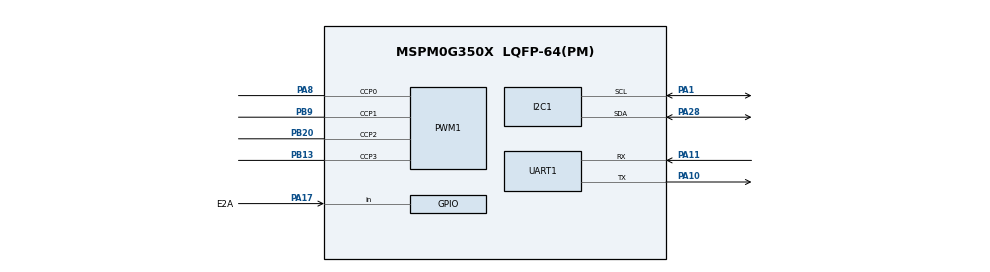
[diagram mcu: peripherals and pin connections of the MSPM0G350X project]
/**
 *
 * @cliArgs --device "MSPM0G350X" --part "Default" --package "LQFP-64(PM)" --product "mspm0_sdk@2.10.00.04"
 * @versions {"tool":"1.28.1+4785"}
 */

/**
 * Import the modules used in this configuration.
 */
const ADC12   = scripting.addModule("/ti/driverlib/ADC12", {}, false);
const ADC121  = ADC12.addInstance();
const GPIO    = scripting.addModule("/ti/driverlib/GPIO", {}, false);
const GPIO1   = GPIO.addInstance();
const GPIO2   = GPIO.addInstance();
const GPIO3   = GPIO.addInstance();
const GPIO4   = GPIO.addInstance();
const GPIO5   = GPIO.addInstance();
const GPIO6   = GPIO.addInstance();
const GPIO7   = GPIO.addInstance();
const GPIO8   = GPIO.addInstance();
const GPIO9   = GPIO.addInstance();
const GPIO10  = GPIO.addInstance();
const GPIO11  = GPIO.addInstance();
const GPIO12  = GPIO.addInstance();
const GPIO13  = GPIO.addInstance();
const GPIO14  = GPIO.addInstance();
const GPIO15  = GPIO.addInstance();
const I2C     = scripting.addModule("/ti/driverlib/I2C", {}, false);
const I2C1    = I2C.addInstance();
const PWM     = scripting.addModule("/ti/driverlib/PWM", {}, false);
const PWM1    = PWM.addInstance();
const SYSCTL  = scripting.addModule("/ti/driverlib/SYSCTL");
const SYSTICK = scripting.addModule("/ti/driverlib/SYSTICK");
const TIMER   = scripting.addModule("/ti/driverlib/TIMER", {}, false);
const TIMER1  = TIMER.addInstance();
const UART    = scripting.addModule("/ti/driverlib/UART", {}, false);
const UART1   = UART.addInstance();

/**
 * Write custom configuration values to the imported modules.
 */
const gate7  = system.clockTree["MFCLKGATE"];
gate7.enable = true;

ADC121.$name                      = "ADC12_0";
ADC121.sampClkSrc                 = "DL_ADC12_CLOCK_ULPCLK";
ADC121.repeatMode                 = true;
ADC121.sampleTime0                = "2 us";
ADC121.peripheral.adcPin0.$assign = "PA27";
ADC121.adcPin0Config.$name        = "ti_driverlib_gpio_GPIOPinGeneric8";

const Board = scripting.addModule("/ti/driverlib/Board", {}, false);

GPIO1.$name                          = "LED1";
GPIO1.associatedPins[0].$name        = "PIN_0";
GPIO1.associatedPins[0].assignedPort = "PORTA";
GPIO1.associatedPins[0].assignedPin  = "0";
GPIO1.associatedPins[0].initialValue = "SET";

GPIO2.$name                              = "KEY";
GPIO2.associatedPins.create(3);
GPIO2.associatedPins[0].direction        = "INPUT";
GPIO2.associatedPins[0].internalResistor = "PULL_UP";
GPIO2.associatedPins[0].assignedPort     = "PORTB";
GPIO2.associatedPins[0].assignedPin      = "21";
GPIO2.associatedPins[0].$name            = "button1";
GPIO2.associatedPins[1].$name            = "button2";
GPIO2.associatedPins[1].direction        = "INPUT";
GPIO2.associatedPins[1].assignedPort     = "PORTB";
GPIO2.associatedPins[1].assignedPin      = "23";
GPIO2.associatedPins[1].internalResistor = "PULL_UP";
GPIO2.associatedPins[2].$name            = "button3";
GPIO2.associatedPins[2].direction        = "INPUT";
GPIO2.associatedPins[2].assignedPort     = "PORTA";
GPIO2.associatedPins[2].assignedPin      = "23";
GPIO2.associatedPins[2].internalResistor = "PULL_UP";

GPIO3.$name                          = "ENCODERA";
GPIO3.associatedPins.create(2);
GPIO3.associatedPins[0].$name        = "E1A";
GPIO3.associatedPins[0].direction    = "INPUT";
GPIO3.associatedPins[0].assignedPort = "PORTA";
GPIO3.associatedPins[0].interruptEn  = true;
GPIO3.associatedPins[0].polarity     = "RISE";
GPIO3.associatedPins[0].assignedPin  = "15";
GPIO3.associatedPins[1].$name        = "E1B";
GPIO3.associatedPins[1].direction    = "INPUT";
GPIO3.associatedPins[1].assignedPort = "PORTA";
GPIO3.associatedPins[1].assignedPin  = "16";
GPIO3.associatedPins[1].interruptEn  = true;
GPIO3.associatedPins[1].polarity     = "RISE";

GPIO4.$name                          = "ENCODERB";
GPIO4.associatedPins.create(2);
GPIO4.associatedPins[0].$name        = "E2A";
GPIO4.associatedPins[0].direction    = "INPUT";
GPIO4.associatedPins[0].assignedPort = "PORTA";
GPIO4.associatedPins[0].assignedPin  = "17";
GPIO4.associatedPins[0].polarity     = "RISE";
GPIO4.associatedPins[0].interruptEn  = true;
GPIO4.associatedPins[0].pin.$assign  = "PA17";
GPIO4.associatedPins[1].$name        = "E2B";
GPIO4.associatedPins[1].direction    = "INPUT";
GPIO4.associatedPins[1].assignedPort = "PORTA";
GPIO4.associatedPins[1].assignedPin  = "22";
GPIO4.associatedPins[1].interruptEn  = true;
GPIO4.associatedPins[1].polarity     = "RISE";

GPIO5.$name                          = "AIN1";
GPIO5.associatedPins[0].$name        = "PIN_12";
GPIO5.associatedPins[0].assignedPort = "PORTB";
GPIO5.associatedPins[0].assignedPin  = "2";

GPIO6.$name                          = "AIN2";
GPIO6.associatedPins[0].$name        = "PIN_13";
GPIO6.associatedPins[0].assignedPort = "PORTB";
GPIO6.associatedPins[0].assignedPin  = "3";

GPIO7.$name                          = "BIN1";
GPIO7.associatedPins[0].$name        = "Pin_Bin1";
GPIO7.associatedPins[0].assignedPort = "PORTB";
GPIO7.associatedPins[0].assignedPin  = "16";

GPIO8.$name                          = "BIN2";
GPIO8.associatedPins[0].$name        = "Pin_Bin2";
GPIO8.associatedPins[0].assignedPort = "PORTB";
GPIO8.associatedPins[0].assignedPin  = "0";

GPIO9.$name                          = "ENCODERC";
GPIO9.associatedPins.create(2);
GPIO9.associatedPins[0].$name        = "PIN_1";
GPIO9.associatedPins[0].direction    = "INPUT";
GPIO9.associatedPins[0].assignedPort = "PORTB";
GPIO9.associatedPins[0].assignedPin  = "6";
GPIO9.associatedPins[0].interruptEn  = true;
GPIO9.associatedPins[0].polarity     = "RISE";
GPIO9.associatedPins[1].$name        = "PIN_2";
GPIO9.associatedPins[1].direction    = "INPUT";
GPIO9.associatedPins[1].assignedPort = "PORTB";
GPIO9.associatedPins[1].assignedPin  = "7";
GPIO9.associatedPins[1].interruptEn  = true;
GPIO9.associatedPins[1].polarity     = "RISE";

GPIO10.$name                          = "ENCODERD";
GPIO10.associatedPins.create(2);
GPIO10.associatedPins[0].$name        = "PIN_3";
GPIO10.associatedPins[0].direction    = "INPUT";
GPIO10.associatedPins[0].assignedPort = "PORTB";
GPIO10.associatedPins[0].assignedPin  = "8";
GPIO10.associatedPins[0].interruptEn  = true;
GPIO10.associatedPins[0].polarity     = "RISE";
GPIO10.associatedPins[1].$name        = "PIN_4";
GPIO10.associatedPins[1].direction    = "INPUT";
GPIO10.associatedPins[1].assignedPort = "PORTB";
GPIO10.associatedPins[1].assignedPin  = "15";
GPIO10.associatedPins[1].interruptEn  = true;
GPIO10.associatedPins[1].polarity     = "RISE";

GPIO11.$name                          = "CIN1";
GPIO11.associatedPins[0].$name        = "PIN_5";
GPIO11.associatedPins[0].assignedPort = "PORTB";
GPIO11.associatedPins[0].assignedPin  = "17";

GPIO12.$name                          = "CIN2";
GPIO12.associatedPins[0].$name        = "PIN_6";
GPIO12.associatedPins[0].assignedPort = "PORTB";
GPIO12.associatedPins[0].assignedPin  = "12";

GPIO13.$name                          = "DIN1";
GPIO13.associatedPins[0].$name        = "PIN_7";
GPIO13.associatedPins[0].assignedPort = "PORTB";
GPIO13.associatedPins[0].assignedPin  = "1";

GPIO14.$name                          = "DIN2";
GPIO14.associatedPins[0].$name        = "PIN_8";
GPIO14.associatedPins[0].assignedPort = "PORTB";
GPIO14.associatedPins[0].assignedPin  = "4";

GPIO15.$name                          = "SENSOR_MUX";
GPIO15.associatedPins.create(3);
GPIO15.associatedPins[0].$name        = "AD0";
GPIO15.associatedPins[0].assignedPort = "PORTA";
GPIO15.associatedPins[0].assignedPin  = "24";
GPIO15.associatedPins[1].$name        = "AD1";
GPIO15.associatedPins[1].assignedPort = "PORTB";
GPIO15.associatedPins[1].assignedPin  = "24";
GPIO15.associatedPins[2].$name        = "AD2";
GPIO15.associatedPins[2].assignedPort = "PORTA";
GPIO15.associatedPins[2].assignedPin  = "30";

I2C1.$name                           = "I2C_0";
I2C1.basicEnableController           = true;
I2C1.basicControllerStandardBusSpeed = "Fast";
I2C1.peripheral.$assign              = "I2C0";
I2C1.peripheral.sdaPin.$assign       = "PA28";
I2C1.peripheral.sclPin.$assign       = "PA1";
I2C1.sdaPinConfig.$name              = "ti_driverlib_gpio_GPIOPinGeneric6";
I2C1.sdaPinConfig.enableConfig       = true;
I2C1.sclPinConfig.$name              = "ti_driverlib_gpio_GPIOPinGeneric7";
I2C1.sclPinConfig.enableConfig       = true;

PWM1.$name                      = "PWM_0";
PWM1.timerStartTimer            = true;
PWM1.ccIndex                    = [0,1,2,3];
PWM1.pwmMode                    = "CENTER_ALIGN";
PWM1.PWM_CHANNEL_0.$name        = "ti_driverlib_pwm_PWMTimerCC0";
PWM1.PWM_CHANNEL_0.invert       = true;
PWM1.PWM_CHANNEL_0.ccValue      = 0;
PWM1.PWM_CHANNEL_1.$name        = "ti_driverlib_pwm_PWMTimerCC1";
PWM1.PWM_CHANNEL_1.invert       = true;
PWM1.PWM_CHANNEL_1.ccValue      = 0;
PWM1.ccp0PinConfig.$name        = "ti_driverlib_gpio_GPIOPinGeneric2";
PWM1.ccp1PinConfig.$name        = "ti_driverlib_gpio_GPIOPinGeneric3";
PWM1.peripheral.$assign         = "TIMA0";
PWM1.peripheral.ccp0Pin.$assign = "PA8";
PWM1.peripheral.ccp1Pin.$assign = "PB9";
PWM1.peripheral.ccp2Pin.$assign = "PB20";
PWM1.peripheral.ccp3Pin.$assign = "PB13";
PWM1.PWM_CHANNEL_2.$name        = "ti_driverlib_pwm_PWMTimerCC2";
PWM1.PWM_CHANNEL_2.invert       = true;
PWM1.PWM_CHANNEL_2.ccValue      = 0;
PWM1.PWM_CHANNEL_3.$name        = "ti_driverlib_pwm_PWMTimerCC3";
PWM1.PWM_CHANNEL_3.invert       = true;
PWM1.PWM_CHANNEL_3.ccValue      = 0;
PWM1.ccp2PinConfig.$name        = "ti_driverlib_gpio_GPIOPinGeneric4";
PWM1.ccp3PinConfig.$name        = "ti_driverlib_gpio_GPIOPinGeneric5";

SYSCTL.forceDefaultClkConfig = true;
SYSCTL.clockTreeEn           = true;

SYSTICK.periodEnable  = true;
SYSTICK.period        = 32;
SYSTICK.systickEnable = true;

TIMER1.$name            = "TIMER_0";
TIMER1.timerClkDiv      = 8;
TIMER1.timerClkPrescale = 200;
TIMER1.timerStartTimer  = true;
TIMER1.interrupts       = ["ZERO"];
TIMER1.timerMode        = "PERIODIC";
TIMER1.timerPeriod      = "10 ms";

UART1.$name                    = "UART_0";
UART1.targetBaudRate           = 115200;
UART1.enabledInterrupts        = ["RX","TX"];
UART1.peripheral.$assign       = "UART0";
UART1.peripheral.rxPin.$assign = "PA11";
UART1.peripheral.txPin.$assign = "PA10";
UART1.txPinConfig.$name        = "ti_driverlib_gpio_GPIOPinGeneric0";
UART1.rxPinConfig.$name        = "ti_driverlib_gpio_GPIOPinGeneric1";

/**
 * Pinmux solution for unlocked pins/peripherals. This ensures that minor changes to the automatic solver in a future
 * version of the tool will not impact the pinmux you originally saw.  These lines can be completely deleted in order to
 * re-solve from scratch.
 */
ADC121.peripheral.$suggestSolution            = "ADC0";
Board.peripheral.$suggestSolution             = "DEBUGSS";
Board.peripheral.swclkPin.$suggestSolution    = "PA20";
Board.peripheral.swdioPin.$suggestSolution    = "PA19";
GPIO1.associatedPins[0].pin.$suggestSolution  = "PA0";
GPIO2.associatedPins[0].pin.$suggestSolution  = "PB21";
GPIO2.associatedPins[1].pin.$suggestSolution  = "PB23";
GPIO2.associatedPins[2].pin.$suggestSolution  = "PA23";
GPIO3.associatedPins[0].pin.$suggestSolution  = "PA15";
GPIO3.associatedPins[1].pin.$suggestSolution  = "PA16";
GPIO4.associatedPins[1].pin.$suggestSolution  = "PA22";
GPIO5.associatedPins[0].pin.$suggestSolution  = "PB2";
GPIO6.associatedPins[0].pin.$suggestSolution  = "PB3";
GPIO7.associatedPins[0].pin.$suggestSolution  = "PB16";
GPIO8.associatedPins[0].pin.$suggestSolution  = "PB0";
GPIO9.associatedPins[0].pin.$suggestSolution  = "PB6";
GPIO9.associatedPins[1].pin.$suggestSolution  = "PB7";
GPIO10.associatedPins[0].pin.$suggestSolution = "PB8";
GPIO10.associatedPins[1].pin.$suggestSolution = "PB15";
GPIO11.associatedPins[0].pin.$suggestSolution = "PB17";
GPIO12.associatedPins[0].pin.$suggestSolution = "PB12";
GPIO13.associatedPins[0].pin.$suggestSolution = "PB1";
GPIO14.associatedPins[0].pin.$suggestSolution = "PB4";
GPIO15.associatedPins[0].pin.$suggestSolution = "PA24";
GPIO15.associatedPins[1].pin.$suggestSolution = "PB24";
GPIO15.associatedPins[2].pin.$suggestSolution = "PA30";
TIMER1.peripheral.$suggestSolution            = "TIMA1";
